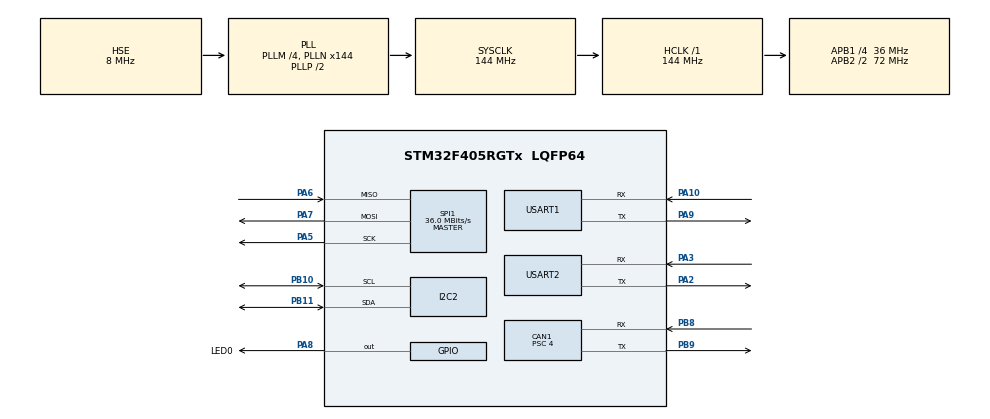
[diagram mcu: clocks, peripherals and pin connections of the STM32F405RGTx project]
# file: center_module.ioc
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CAN1.ABOM=ENABLE
CAN1.BS1=CAN_BS1_3TQ
CAN1.BS2=CAN_BS2_5TQ
CAN1.CalculateBaudRate=1000000
CAN1.CalculateTimeBit=1000
CAN1.CalculateTimeQuantum=111.11111111111111
CAN1.Mode=CAN_MODE_NORMAL
CAN1.Prescaler=4
CAN1.RFLM=ENABLE
CAN1.TXFP=ENABLE
Dma.Request0=SPI1_RX
Dma.Request1=SPI1_TX
Dma.SPI1_RX.0.Direction=DMA_PERIPH_TO_MEMORY
Dma.SPI1_RX.0.FIFOMode=DMA_FIFOMODE_DISABLE
Dma.SPI1_RX.0.Instance=DMA2_Stream0
Dma.SPI1_RX.0.MemDataAlignment=DMA_MDATAALIGN_BYTE
Dma.SPI1_RX.0.MemInc=DMA_MINC_ENABLE
Dma.SPI1_RX.0.Mode=DMA_NORMAL
Dma.SPI1_RX.0.PeriphDataAlignment=DMA_PDATAALIGN_BYTE
Dma.SPI1_RX.0.PeriphInc=DMA_PINC_DISABLE
Dma.SPI1_RX.0.Priority=DMA_PRIORITY_LOW
Dma.SPI1_TX.1.Direction=DMA_MEMORY_TO_PERIPH
Dma.SPI1_TX.1.FIFOMode=DMA_FIFOMODE_DISABLE
Dma.SPI1_TX.1.Instance=DMA2_Stream3
Dma.SPI1_TX.1.MemDataAlignment=DMA_MDATAALIGN_BYTE
Dma.SPI1_TX.1.MemInc=DMA_MINC_ENABLE
Dma.SPI1_TX.1.Mode=DMA_NORMAL
Dma.SPI1_TX.1.PeriphDataAlignment=DMA_PDATAALIGN_BYTE
Dma.SPI1_TX.1.PeriphInc=DMA_PINC_DISABLE
Dma.SPI1_TX.1.Priority=DMA_PRIORITY_LOW
FREERTOS.Tasks01=defaultTask,24,128,StartDefaultTask,Default,NULL,Dynamic,NULL,NULL
FREERTOS.configCHECK_FOR_STACK_OVERFLOW=1
FREERTOS.configENABLE_FPU=1
FREERTOS.configMAX_TASK_NAME_LEN=32
FREERTOS.configTOTAL_HEAP_SIZE=65536
FREERTOS.configUSE_NEWLIB_REENTRANT=1
I2C2.I2C_Mode=I2C_Fast
Mcu.Family=STM32F4
Mcu.Name=STM32F405RGTx
Mcu.Package=LQFP64
NVIC.CAN1_RX0_IRQn=true\:5\:0\:false\:false\:true\:true\:true\:true\:true
NVIC.DMA2_Stream0_IRQn=true\:5\:0\:false\:false\:true\:true\:false\:true\:true
NVIC.DMA2_Stream3_IRQn=true\:5\:0\:false\:false\:true\:true\:false\:true\:true
NVIC.I2C2_EV_IRQn=true\:5\:0\:false\:false\:true\:true\:true\:true\:true
NVIC.PriorityGroup=NVIC_PRIORITYGROUP_4
NVIC.SPI1_IRQn=true\:5\:0\:false\:false\:true\:true\:true\:true\:true
NVIC.TIM6_DAC_IRQn=true\:15\:0\:false\:false\:true\:false\:false\:true\:true
NVIC.TimeBase=TIM6_DAC_IRQn
NVIC.TimeBaseIP=TIM6
NVIC.USART1_IRQn=true\:5\:0\:false\:false\:true\:true\:true\:true\:true
NVIC.USART2_IRQn=true\:5\:0\:false\:false\:true\:true\:true\:true\:true
PA10.Mode=Asynchronous
PA10.Signal=USART1_RX
PA13.Mode=Serial_Wire
PA13.Signal=SYS_JTMS-SWDIO
PA14.Mode=Serial_Wire
PA14.Signal=SYS_JTCK-SWCLK
PA2.Mode=Asynchronous
PA2.Signal=USART2_TX
PA3.Mode=Asynchronous
PA3.Signal=USART2_RX
PA5.Mode=Full_Duplex_Master
PA5.Signal=SPI1_SCK
PA6.Mode=Full_Duplex_Master
PA6.Signal=SPI1_MISO
PA7.Mode=Full_Duplex_Master
PA7.Signal=SPI1_MOSI
PA8.GPIO_Label=LED0
PA8.GPIO_ModeDefaultOutputPP=GPIO_MODE_OUTPUT_PP
PA8.GPIO_PuPd=GPIO_PULLUP
PA8.GPIO_Speed=GPIO_SPEED_FREQ_VERY_HIGH
PA8.PinState=GPIO_PIN_SET
PA8.Signal=GPIO_Output
PA9.Mode=Asynchronous
PA9.Signal=USART1_TX
PB10.Mode=I2C
PB10.Signal=I2C2_SCL
PB11.Mode=I2C
PB11.Signal=I2C2_SDA
PB8.Mode=CAN_Activate
PB8.Signal=CAN1_RX
PB9.Mode=CAN_Activate
PB9.Signal=CAN1_TX
PH0-OSC_IN.Mode=HSE-External-Oscillator
PH0-OSC_IN.Signal=RCC_OSC_IN
PH1-OSC_OUT.Mode=HSE-External-Oscillator
PH1-OSC_OUT.Signal=RCC_OSC_OUT
ProjectManager.HeapSize=0x200
ProjectManager.StackSize=0x400
ProjectManager.TargetToolchain=STM32CubeIDE
RCC.48MHZClocksFreq_Value=41142857.14285714
RCC.AHBFreq_Value=144000000
RCC.APB1CLKDivider=RCC_HCLK_DIV4
RCC.APB1Freq_Value=36000000
RCC.APB1TimFreq_Value=72000000
RCC.APB2CLKDivider=RCC_HCLK_DIV2
RCC.APB2Freq_Value=72000000
RCC.APB2TimFreq_Value=144000000
RCC.CortexFreq_Value=144000000
RCC.HCLKFreq_Value=144000000
RCC.HSE_VALUE=8000000
RCC.HSI_VALUE=16000000
RCC.LSE_VALUE=32768
RCC.PLLM=4
RCC.PLLN=144
RCC.PLLQ=7
RCC.PLLSourceVirtual=RCC_PLLSOURCE_HSE
RCC.SYSCLKFreq_VALUE=144000000
RCC.SYSCLKSource=RCC_SYSCLKSOURCE_PLLCLK
RCC.VCOOutputFreq_Value=288000000
SPI1.BaudRatePrescaler=SPI_BAUDRATEPRESCALER_2
SPI1.CalculateBaudRate=36.0 MBits/s
SPI1.Direction=SPI_DIRECTION_2LINES
SPI1.Mode=SPI_MODE_MASTER
SPI1.VirtualType=VM_MASTER
USART1.VirtualMode=VM_ASYNC
USART2.VirtualMode=VM_ASYNC
VP_FREERTOS_VS_CMSIS_V2.Mode=CMSIS_V2
VP_SYS_VS_tim6.Mode=TIM6
board=custom

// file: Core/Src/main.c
/* USER CODE BEGIN Header */
/**
  ******************************************************************************
  * @file           : main.c
  * @brief          : Main program body
  ******************************************************************************
  * @attention
  *
  * Copyright (c) 2024 STMicroelectronics.
  * All rights reserved.
  *
  * This software is licensed under terms that can be found in the LICENSE file
  * in the root directory of this software component.
  * If no LICENSE file comes with this software, it is provided AS-IS.
  *
  ******************************************************************************
  */
/* USER CODE END Header */
#include "main.h"
#include "cmsis_os.h"
#include "can.h"
#include "dma.h"
#include "i2c.h"
#include "spi.h"
#include "usart.h"
#include "gpio.h"

void SystemClock_Config(void);
void MX_FREERTOS_Init(void);

int main(void)
{

  /* MCU Configuration--------------------------------------------------------*/

  /* Reset of all peripherals, Initializes the Flash interface and the Systick. */
  HAL_Init();

  /* Configure the system clock */
  SystemClock_Config();

  /* Initialize all configured peripherals */
  MX_GPIO_Init();
  MX_DMA_Init();
  MX_CAN1_Init();
  MX_SPI1_Init();
  MX_USART1_UART_Init();
  MX_USART2_UART_Init();
  MX_I2C2_Init();
  /* USER CODE BEGIN 2 */
  // char init_msg[] = "usart2 initialized\n";
  // HAL_UART_Transmit(&huart2, (uint8_t*)init_msg, sizeof(init_msg) - 1, HAL_MAX_DELAY);

  // HAL_UART_Transmit(&huart2, (uint8_t*)"100\r\n", 5, 0xffffffff);
  // MPU_Init();
  /* USER CODE END 2 */

  // HAL_UART_Transmit(&huart2, (uint8_t*)"113\r\n", 5, 0xffffffff);
  /* Init scheduler */
  osKernelInitialize();  /* Call init function for freertos objects (in freertos.c) */
  MX_FREERTOS_Init();

  // HAL_UART_Transmit(&huart2, (uint8_t*)"114\r\n", 5, 0xffffffff);
  /* Start scheduler */
  startThreads();
  osKernelStart();

  /* We should never get here as control is now taken by the scheduler */
  /* Infinite loop */
  while (1)
  {

  }
}

void SystemClock_Config(void)
{
  RCC_OscInitTypeDef RCC_OscInitStruct = {0};
  RCC_ClkInitTypeDef RCC_ClkInitStruct = {0};

  /** Configure the main internal regulator output voltage
  */
  __HAL_RCC_PWR_CLK_ENABLE();
  __HAL_PWR_VOLTAGESCALING_CONFIG(PWR_REGULATOR_VOLTAGE_SCALE1);

  /** Initializes the RCC Oscillators according to the specified parameters
  * in the RCC_OscInitTypeDef structure.
  */
  RCC_OscInitStruct.OscillatorType = RCC_OSCILLATORTYPE_HSE;
  RCC_OscInitStruct.HSEState = RCC_HSE_ON;
  RCC_OscInitStruct.PLL.PLLState = RCC_PLL_ON;
  RCC_OscInitStruct.PLL.PLLSource = RCC_PLLSOURCE_HSE;
  RCC_OscInitStruct.PLL.PLLM = 4;
  RCC_OscInitStruct.PLL.PLLN = 144;
  RCC_OscInitStruct.PLL.PLLP = RCC_PLLP_DIV2;
  RCC_OscInitStruct.PLL.PLLQ = 7;
  if (HAL_RCC_OscConfig(&RCC_OscInitStruct) != HAL_OK)
  {
    Error_Handler();
  }

  /** Initializes the CPU, AHB and APB buses clocks
  */
  RCC_ClkInitStruct.ClockType = RCC_CLOCKTYPE_HCLK|RCC_CLOCKTYPE_SYSCLK
                              |RCC_CLOCKTYPE_PCLK1|RCC_CLOCKTYPE_PCLK2;
  RCC_ClkInitStruct.SYSCLKSource = RCC_SYSCLKSOURCE_PLLCLK;
  RCC_ClkInitStruct.AHBCLKDivider = RCC_SYSCLK_DIV1;
  RCC_ClkInitStruct.APB1CLKDivider = RCC_HCLK_DIV4;
  RCC_ClkInitStruct.APB2CLKDivider = RCC_HCLK_DIV2;

  if (HAL_RCC_ClockConfig(&RCC_ClkInitStruct, FLASH_LATENCY_4) != HAL_OK)
  {
    Error_Handler();
  }
}

void HAL_TIM_PeriodElapsedCallback(TIM_HandleTypeDef *htim)
{
  if (htim->Instance == TIM6) {
    HAL_IncTick();
  }
}

void Error_Handler(void)
{
  __disable_irq();
  while (1)
  {
  }
}

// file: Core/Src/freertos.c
/* USER CODE BEGIN Header */
/**
  ******************************************************************************
  * File Name          : freertos.c
  * Description        : Code for freertos applications
  ******************************************************************************
  * @attention
  *
  * Copyright (c) 2024 STMicroelectronics.
  * All rights reserved.
  *
  * This software is licensed under terms that can be found in the LICENSE file
  * in the root directory of this software component.
  * If no LICENSE file comes with this software, it is provided AS-IS.
  *
  ******************************************************************************
  */
/* USER CODE END Header */

#include "FreeRTOS.h"
#include "task.h"
#include "main.h"
#include "cmsis_os.h"

/* Definitions for defaultTask */
osThreadId_t defaultTaskHandle;
const osThreadAttr_t defaultTask_attributes = {
  .name = "defaultTask",
  .stack_size = 128 * 4,
  .priority = (osPriority_t) osPriorityNormal,
};

void StartDefaultTask(void *argument);

void MX_FREERTOS_Init(void); /* (MISRA C 2004 rule 8.1) */

/* Hook prototypes */
void vApplicationStackOverflowHook(xTaskHandle xTask, signed char *pcTaskName);

/* USER CODE BEGIN 4 */
void vApplicationStackOverflowHook(xTaskHandle xTask, signed char *pcTaskName)
{
   /* Run time stack overflow checking is performed if
   configCHECK_FOR_STACK_OVERFLOW is defined to 1 or 2. This hook function is
   called if a stack overflow is detected. */
}
/* USER CODE END 4 */

void MX_FREERTOS_Init(void) {

  /* Create the thread(s) */
  /* creation of defaultTask */
  defaultTaskHandle = osThreadNew(StartDefaultTask, NULL, &defaultTask_attributes);

}

void StartDefaultTask(void *argument)
{
  /* USER CODE BEGIN StartDefaultTask */
  /* Infinite loop */
    while (1) {
        HAL_GPIO_TogglePin(LED0_GPIO_Port, LED0_Pin);
        osDelay(pdMS_TO_TICKS(500));
    }
  /* USER CODE END StartDefaultTask */
}
